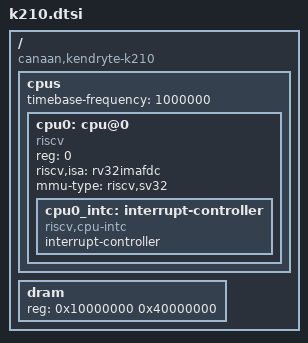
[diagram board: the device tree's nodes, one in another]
// SPDX-License-Identifier: GPL-2.0+
/*
 * Copyright (C) 2019-20 Sean Anderson <seanga2@gmail.com>
 * Copyright (C) 2020 Western Digital Corporation or its affiliates.
 */
#include <dt-bindings/clock/k210-clk.h>
#include <dt-bindings/pinctrl/k210-fpioa.h>
#include <dt-bindings/reset/k210-rst.h>

/ {
	/*
	 * Although the K210 is a 64-bit CPU, the address bus is only 32-bits
	 * wide, and the upper half of all addresses is ignored.
	 */
	#address-cells = <1>;
	#size-cells = <1>;
	compatible = "canaan,kendryte-k210";

	/*
	 * The K210 has an sv39 MMU following the privileged specification v1.9.
	 * Since this is a non-ratified draft specification, the kernel does not
	 * support it and the K210 support enabled only for the !MMU case.
	 * Be consistent with this by setting the CPUs MMU type to "none".
	 */
	cpus {
		#address-cells = <1>;
		#size-cells = <0>;
		timebase-frequency = <1000000>;
		cpu0: cpu@0 {
			device_type = "cpu";
			compatible = "riscv";
			reg = <0>;
			riscv,isa = "rv32imafdc";
			mmu-type = "riscv,sv32";
			cpu0_intc: interrupt-controller {
				#interrupt-cells = <1>;
				interrupt-controller;
				compatible = "riscv,cpu-intc";
			};
		};
	};

	dram {
		device_type = "memory";
		reg = <0x10000000 0x40000000>;
	};
};
